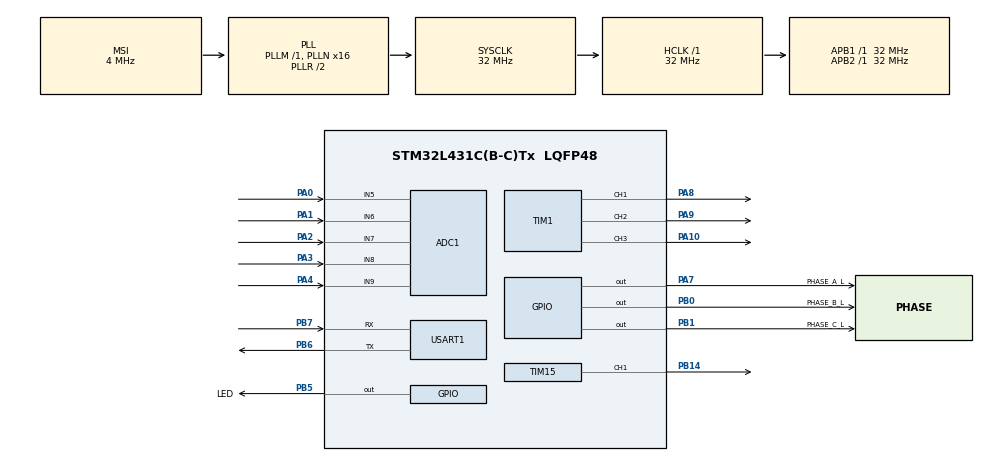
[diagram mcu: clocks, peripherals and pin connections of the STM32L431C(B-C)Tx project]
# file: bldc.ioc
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ADC1.Channel-0\#ChannelRegularConversion=ADC_CHANNEL_5
ADC1.NbrOfConversionFlag=1
ADC1.OffsetNumber-0\#ChannelRegularConversion=ADC_OFFSET_NONE
ADC1.Rank-0\#ChannelRegularConversion=1
ADC1.SamplingTime-0\#ChannelRegularConversion=ADC_SAMPLETIME_2CYCLES_5
ADC1.master=1
Mcu.Family=STM32L4
Mcu.Name=STM32L431C(B-C)Tx
Mcu.Package=LQFP48
NVIC.PriorityGroup=NVIC_PRIORITYGROUP_4
PA0.Signal=ADCx_IN5
PA1.Signal=ADCx_IN6
PA10.Signal=S_TIM1_CH3
PA13\ (JTMS-SWDIO).Mode=Serial_Wire
PA13\ (JTMS-SWDIO).Signal=SYS_JTMS-SWDIO
PA14\ (JTCK-SWCLK).Mode=Serial_Wire
PA14\ (JTCK-SWCLK).Signal=SYS_JTCK-SWCLK
PA2.Signal=ADCx_IN7
PA3.Signal=ADCx_IN8
PA4.Signal=ADCx_IN9
PA7.GPIO_Label=PHASE_A_L
PA7.Signal=GPIO_Output
PA8.Signal=S_TIM1_CH1
PA9.Signal=S_TIM1_CH2
PB0.GPIO_Label=PHASE_B_L
PB0.Signal=GPIO_Output
PB1.GPIO_Label=PHASE_C_L
PB1.Signal=GPIO_Output
PB14.Signal=S_TIM15_CH1
PB5.GPIO_Label=LED
PB5.Signal=GPIO_Output
PB6.Mode=Asynchronous
PB6.Signal=USART1_TX
PB7.Mode=Asynchronous
PB7.Signal=USART1_RX
ProjectManager.HeapSize=0x200
ProjectManager.StackSize=0x400
ProjectManager.TargetToolchain=STM32CubeIDE
RCC.ADCFreq_Value=32000000
RCC.AHBFreq_Value=32000000
RCC.APB1Freq_Value=32000000
RCC.APB1TimFreq_Value=32000000
RCC.APB2Freq_Value=32000000
RCC.APB2TimFreq_Value=32000000
RCC.CortexFreq_Value=32000000
RCC.HCLKFreq_Value=32000000
RCC.HSE_VALUE=8000000
RCC.HSI48_VALUE=48000000
RCC.HSI_VALUE=16000000
RCC.LSE_VALUE=32768
RCC.MSI_VALUE=4000000
RCC.PLLN=16
RCC.PLLSAI1N=16
RCC.SYSCLKFreq_VALUE=32000000
RCC.SYSCLKSource=RCC_SYSCLKSOURCE_PLLCLK
RCC.VCOOutputFreq_Value=64000000
SH.ADCx_IN5.0=ADC1_IN5,IN5-Single-Ended
SH.ADCx_IN6.0=ADC1_IN6,IN6-Single-Ended
SH.ADCx_IN7.0=ADC1_IN7,IN7-Single-Ended
SH.ADCx_IN8.0=ADC1_IN8,IN8-Single-Ended
SH.ADCx_IN9.0=ADC1_IN9,IN9-Single-Ended
SH.S_TIM15_CH1.0=TIM15_CH1,PWM Generation1 CH1
SH.S_TIM1_CH1.0=TIM1_CH1,PWM Generation1 CH1
SH.S_TIM1_CH2.0=TIM1_CH2,PWM Generation2 CH2
SH.S_TIM1_CH3.0=TIM1_CH3,PWM Generation3 CH3
TIM1.Channel-PWM\ Generation1\ CH1=TIM_CHANNEL_1
TIM1.Channel-PWM\ Generation2\ CH2=TIM_CHANNEL_2
TIM1.Channel-PWM\ Generation3\ CH3=TIM_CHANNEL_3
TIM15.Channel-PWM\ Generation1\ CH1=TIM_CHANNEL_1
USART1.VirtualMode-Asynchronous=VM_ASYNC
VP_TIM15_VS_ClockSourceINT.Mode=Internal
VP_TIM1_VS_ClockSourceINT.Mode=Internal
board=custom

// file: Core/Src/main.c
/* USER CODE BEGIN Header */
/**
  ******************************************************************************
  * @file           : main.c
  * @brief          : Main program body
  ******************************************************************************
  * @attention
  *
  * Copyright (c) 2025 STMicroelectronics.
  * All rights reserved.
  *
  * This software is licensed under terms that can be found in the LICENSE file
  * in the root directory of this software component.
  * If no LICENSE file comes with this software, it is provided AS-IS.
  *
  ******************************************************************************
  */
/* USER CODE END Header */
#include "main.h"

/* USER CODE BEGIN Includes */
#include "bldc.h"
/* USER CODE END Includes */

ADC_HandleTypeDef hadc1;

TIM_HandleTypeDef htim1;
TIM_HandleTypeDef htim15;

UART_HandleTypeDef huart1;

void SystemClock_Config(void);
static void MX_GPIO_Init(void);
static void MX_ADC1_Init(void);
static void MX_TIM1_Init(void);
static void MX_TIM15_Init(void);
static void MX_USART1_UART_Init(void);

int main(void)
{

  /* MCU Configuration--------------------------------------------------------*/

  /* Reset of all peripherals, Initializes the Flash interface and the Systick. */
  HAL_Init();

  /* Configure the system clock */
  SystemClock_Config();

  /* Initialize all configured peripherals */
  MX_GPIO_Init();
  MX_ADC1_Init();
  MX_TIM1_Init();
  MX_TIM15_Init();
  MX_USART1_UART_Init();
  /* USER CODE BEGIN 2 */
  //BLDC_Init();
  BLDC_Start(30);

  /* USER CODE END 2 */

  /* Infinite loop */
  /* USER CODE BEGIN WHILE */
  while (1)
  {
	// Application code

    /* USER CODE END WHILE */

    /* USER CODE BEGIN 3 */
	BLDC_loop();

  }
  /* USER CODE END 3 */
}

void SystemClock_Config(void)
{
  RCC_OscInitTypeDef RCC_OscInitStruct = {0};
  RCC_ClkInitTypeDef RCC_ClkInitStruct = {0};

  /** Configure the main internal regulator output voltage
  */
  if (HAL_PWREx_ControlVoltageScaling(PWR_REGULATOR_VOLTAGE_SCALE1) != HAL_OK)
  {
    Error_Handler();
  }

  /** Initializes the RCC Oscillators according to the specified parameters
  * in the RCC_OscInitTypeDef structure.
  */
  RCC_OscInitStruct.OscillatorType = RCC_OSCILLATORTYPE_MSI;
  RCC_OscInitStruct.MSIState = RCC_MSI_ON;
  RCC_OscInitStruct.MSICalibrationValue = 0;
  RCC_OscInitStruct.MSIClockRange = RCC_MSIRANGE_6;
  RCC_OscInitStruct.PLL.PLLState = RCC_PLL_ON;
  RCC_OscInitStruct.PLL.PLLSource = RCC_PLLSOURCE_MSI;
  RCC_OscInitStruct.PLL.PLLM = 1;
  RCC_OscInitStruct.PLL.PLLN = 16;
  RCC_OscInitStruct.PLL.PLLP = RCC_PLLP_DIV7;
  RCC_OscInitStruct.PLL.PLLQ = RCC_PLLQ_DIV2;
  RCC_OscInitStruct.PLL.PLLR = RCC_PLLR_DIV2;
  if (HAL_RCC_OscConfig(&RCC_OscInitStruct) != HAL_OK)
  {
    Error_Handler();
  }

  /** Initializes the CPU, AHB and APB buses clocks
  */
  RCC_ClkInitStruct.ClockType = RCC_CLOCKTYPE_HCLK|RCC_CLOCKTYPE_SYSCLK
                              |RCC_CLOCKTYPE_PCLK1|RCC_CLOCKTYPE_PCLK2;
  RCC_ClkInitStruct.SYSCLKSource = RCC_SYSCLKSOURCE_PLLCLK;
  RCC_ClkInitStruct.AHBCLKDivider = RCC_SYSCLK_DIV1;
  RCC_ClkInitStruct.APB1CLKDivider = RCC_HCLK_DIV1;
  RCC_ClkInitStruct.APB2CLKDivider = RCC_HCLK_DIV1;

  if (HAL_RCC_ClockConfig(&RCC_ClkInitStruct, FLASH_LATENCY_1) != HAL_OK)
  {
    Error_Handler();
  }
}

static void MX_ADC1_Init(void)
{

  ADC_ChannelConfTypeDef sConfig = {0};

  /** Common config
  */
  hadc1.Instance = ADC1;
  hadc1.Init.ClockPrescaler = ADC_CLOCK_ASYNC_DIV1;
  hadc1.Init.Resolution = ADC_RESOLUTION_12B;
  hadc1.Init.DataAlign = ADC_DATAALIGN_RIGHT;
  hadc1.Init.ScanConvMode = ADC_SCAN_DISABLE;
  hadc1.Init.EOCSelection = ADC_EOC_SINGLE_CONV;
  hadc1.Init.LowPowerAutoWait = DISABLE;
  hadc1.Init.ContinuousConvMode = DISABLE;
  hadc1.Init.NbrOfConversion = 1;
  hadc1.Init.DiscontinuousConvMode = DISABLE;
  hadc1.Init.ExternalTrigConv = ADC_SOFTWARE_START;
  hadc1.Init.ExternalTrigConvEdge = ADC_EXTERNALTRIGCONVEDGE_NONE;
  hadc1.Init.DMAContinuousRequests = DISABLE;
  hadc1.Init.Overrun = ADC_OVR_DATA_PRESERVED;
  hadc1.Init.OversamplingMode = DISABLE;
  if (HAL_ADC_Init(&hadc1) != HAL_OK)
  {
    Error_Handler();
  }

  /** Configure Regular Channel
  */
  sConfig.Channel = ADC_CHANNEL_5;
  sConfig.Rank = ADC_REGULAR_RANK_1;
  sConfig.SamplingTime = ADC_SAMPLETIME_2CYCLES_5;
  sConfig.SingleDiff = ADC_SINGLE_ENDED;
  sConfig.OffsetNumber = ADC_OFFSET_NONE;
  sConfig.Offset = 0;
  if (HAL_ADC_ConfigChannel(&hadc1, &sConfig) != HAL_OK)
  {
    Error_Handler();
  }

}

static void MX_TIM1_Init(void)
{

  TIM_ClockConfigTypeDef sClockSourceConfig = {0};
  TIM_MasterConfigTypeDef sMasterConfig = {0};
  TIM_OC_InitTypeDef sConfigOC = {0};
  TIM_BreakDeadTimeConfigTypeDef sBreakDeadTimeConfig = {0};

  htim1.Instance = TIM1;
  htim1.Init.Prescaler = 0;
  htim1.Init.CounterMode = TIM_COUNTERMODE_UP;
  htim1.Init.Period = 65535;
  htim1.Init.ClockDivision = TIM_CLOCKDIVISION_DIV1;
  htim1.Init.RepetitionCounter = 0;
  htim1.Init.AutoReloadPreload = TIM_AUTORELOAD_PRELOAD_DISABLE;
  if (HAL_TIM_Base_Init(&htim1) != HAL_OK)
  {
    Error_Handler();
  }
  sClockSourceConfig.ClockSource = TIM_CLOCKSOURCE_INTERNAL;
  if (HAL_TIM_ConfigClockSource(&htim1, &sClockSourceConfig) != HAL_OK)
  {
    Error_Handler();
  }
  if (HAL_TIM_PWM_Init(&htim1) != HAL_OK)
  {
    Error_Handler();
  }
  sMasterConfig.MasterOutputTrigger = TIM_TRGO_RESET;
  sMasterConfig.MasterOutputTrigger2 = TIM_TRGO2_RESET;
  sMasterConfig.MasterSlaveMode = TIM_MASTERSLAVEMODE_DISABLE;
  if (HAL_TIMEx_MasterConfigSynchronization(&htim1, &sMasterConfig) != HAL_OK)
  {
    Error_Handler();
  }
  sConfigOC.OCMode = TIM_OCMODE_PWM1;
  sConfigOC.Pulse = 0;
  sConfigOC.OCPolarity = TIM_OCPOLARITY_HIGH;
  sConfigOC.OCNPolarity = TIM_OCNPOLARITY_HIGH;
  sConfigOC.OCFastMode = TIM_OCFAST_DISABLE;
  sConfigOC.OCIdleState = TIM_OCIDLESTATE_RESET;
  sConfigOC.OCNIdleState = TIM_OCNIDLESTATE_RESET;
  if (HAL_TIM_PWM_ConfigChannel(&htim1, &sConfigOC, TIM_CHANNEL_1) != HAL_OK)
  {
    Error_Handler();
  }
  if (HAL_TIM_PWM_ConfigChannel(&htim1, &sConfigOC, TIM_CHANNEL_2) != HAL_OK)
  {
    Error_Handler();
  }
  if (HAL_TIM_PWM_ConfigChannel(&htim1, &sConfigOC, TIM_CHANNEL_3) != HAL_OK)
  {
    Error_Handler();
  }
  sBreakDeadTimeConfig.OffStateRunMode = TIM_OSSR_DISABLE;
  sBreakDeadTimeConfig.OffStateIDLEMode = TIM_OSSI_DISABLE;
  sBreakDeadTimeConfig.LockLevel = TIM_LOCKLEVEL_OFF;
  sBreakDeadTimeConfig.DeadTime = 0;
  sBreakDeadTimeConfig.BreakState = TIM_BREAK_DISABLE;
  sBreakDeadTimeConfig.BreakPolarity = TIM_BREAKPOLARITY_HIGH;
  sBreakDeadTimeConfig.BreakFilter = 0;
  sBreakDeadTimeConfig.Break2State = TIM_BREAK2_DISABLE;
  sBreakDeadTimeConfig.Break2Polarity = TIM_BREAK2POLARITY_HIGH;
  sBreakDeadTimeConfig.Break2Filter = 0;
  sBreakDeadTimeConfig.AutomaticOutput = TIM_AUTOMATICOUTPUT_DISABLE;
  if (HAL_TIMEx_ConfigBreakDeadTime(&htim1, &sBreakDeadTimeConfig) != HAL_OK)
  {
    Error_Handler();
  }
  HAL_TIM_MspPostInit(&htim1);

}

static void MX_TIM15_Init(void)
{

  TIM_ClockConfigTypeDef sClockSourceConfig = {0};
  TIM_MasterConfigTypeDef sMasterConfig = {0};
  TIM_OC_InitTypeDef sConfigOC = {0};
  TIM_BreakDeadTimeConfigTypeDef sBreakDeadTimeConfig = {0};

  htim15.Instance = TIM15;
  htim15.Init.Prescaler = 0;
  htim15.Init.CounterMode = TIM_COUNTERMODE_UP;
  htim15.Init.Period = 65535;
  htim15.Init.ClockDivision = TIM_CLOCKDIVISION_DIV1;
  htim15.Init.RepetitionCounter = 0;
  htim15.Init.AutoReloadPreload = TIM_AUTORELOAD_PRELOAD_DISABLE;
  if (HAL_TIM_Base_Init(&htim15) != HAL_OK)
  {
    Error_Handler();
  }
  sClockSourceConfig.ClockSource = TIM_CLOCKSOURCE_INTERNAL;
  if (HAL_TIM_ConfigClockSource(&htim15, &sClockSourceConfig) != HAL_OK)
  {
    Error_Handler();
  }
  if (HAL_TIM_PWM_Init(&htim15) != HAL_OK)
  {
    Error_Handler();
  }
  sMasterConfig.MasterOutputTrigger = TIM_TRGO_RESET;
  sMasterConfig.MasterSlaveMode = TIM_MASTERSLAVEMODE_DISABLE;
  if (HAL_TIMEx_MasterConfigSynchronization(&htim15, &sMasterConfig) != HAL_OK)
  {
    Error_Handler();
  }
  sConfigOC.OCMode = TIM_OCMODE_PWM1;
  sConfigOC.Pulse = 0;
  sConfigOC.OCPolarity = TIM_OCPOLARITY_HIGH;
  sConfigOC.OCNPolarity = TIM_OCNPOLARITY_HIGH;
  sConfigOC.OCFastMode = TIM_OCFAST_DISABLE;
  sConfigOC.OCIdleState = TIM_OCIDLESTATE_RESET;
  sConfigOC.OCNIdleState = TIM_OCNIDLESTATE_RESET;
  if (HAL_TIM_PWM_ConfigChannel(&htim15, &sConfigOC, TIM_CHANNEL_1) != HAL_OK)
  {
    Error_Handler();
  }
  sBreakDeadTimeConfig.OffStateRunMode = TIM_OSSR_DISABLE;
  sBreakDeadTimeConfig.OffStateIDLEMode = TIM_OSSI_DISABLE;
  sBreakDeadTimeConfig.LockLevel = TIM_LOCKLEVEL_OFF;
  sBreakDeadTimeConfig.DeadTime = 0;
  sBreakDeadTimeConfig.BreakState = TIM_BREAK_DISABLE;
  sBreakDeadTimeConfig.BreakPolarity = TIM_BREAKPOLARITY_HIGH;
  sBreakDeadTimeConfig.AutomaticOutput = TIM_AUTOMATICOUTPUT_DISABLE;
  if (HAL_TIMEx_ConfigBreakDeadTime(&htim15, &sBreakDeadTimeConfig) != HAL_OK)
  {
    Error_Handler();
  }
  HAL_TIM_MspPostInit(&htim15);

}

static void MX_USART1_UART_Init(void)
{

  huart1.Instance = USART1;
  huart1.Init.BaudRate = 115200;
  huart1.Init.WordLength = UART_WORDLENGTH_8B;
  huart1.Init.StopBits = UART_STOPBITS_1;
  huart1.Init.Parity = UART_PARITY_NONE;
  huart1.Init.Mode = UART_MODE_TX_RX;
  huart1.Init.HwFlowCtl = UART_HWCONTROL_NONE;
  huart1.Init.OverSampling = UART_OVERSAMPLING_16;
  huart1.Init.OneBitSampling = UART_ONE_BIT_SAMPLE_DISABLE;
  huart1.AdvancedInit.AdvFeatureInit = UART_ADVFEATURE_NO_INIT;
  if (HAL_UART_Init(&huart1) != HAL_OK)
  {
    Error_Handler();
  }

}

static void MX_GPIO_Init(void)
{
  GPIO_InitTypeDef GPIO_InitStruct = {0};

  /* GPIO Ports Clock Enable */
  __HAL_RCC_GPIOA_CLK_ENABLE();
  __HAL_RCC_GPIOB_CLK_ENABLE();

  /*Configure GPIO pin Output Level */
  HAL_GPIO_WritePin(PHASE_A_L_GPIO_Port, PHASE_A_L_Pin, GPIO_PIN_RESET);

  /*Configure GPIO pin Output Level */
  HAL_GPIO_WritePin(GPIOB, PHASE_B_L_Pin|PHASE_C_L_Pin|LED_Pin, GPIO_PIN_RESET);

  /*Configure GPIO pin : PHASE_A_L_Pin */
  GPIO_InitStruct.Pin = PHASE_A_L_Pin;
  GPIO_InitStruct.Mode = GPIO_MODE_OUTPUT_PP;
  GPIO_InitStruct.Pull = GPIO_NOPULL;
  GPIO_InitStruct.Speed = GPIO_SPEED_FREQ_LOW;
  HAL_GPIO_Init(PHASE_A_L_GPIO_Port, &GPIO_InitStruct);

  /*Configure GPIO pins : PHASE_B_L_Pin PHASE_C_L_Pin LED_Pin */
  GPIO_InitStruct.Pin = PHASE_B_L_Pin|PHASE_C_L_Pin|LED_Pin;
  GPIO_InitStruct.Mode = GPIO_MODE_OUTPUT_PP;
  GPIO_InitStruct.Pull = GPIO_NOPULL;
  GPIO_InitStruct.Speed = GPIO_SPEED_FREQ_LOW;
  HAL_GPIO_Init(GPIOB, &GPIO_InitStruct);

}

void Error_Handler(void)
{
  __disable_irq();
  while (1)
  {
  }
}
